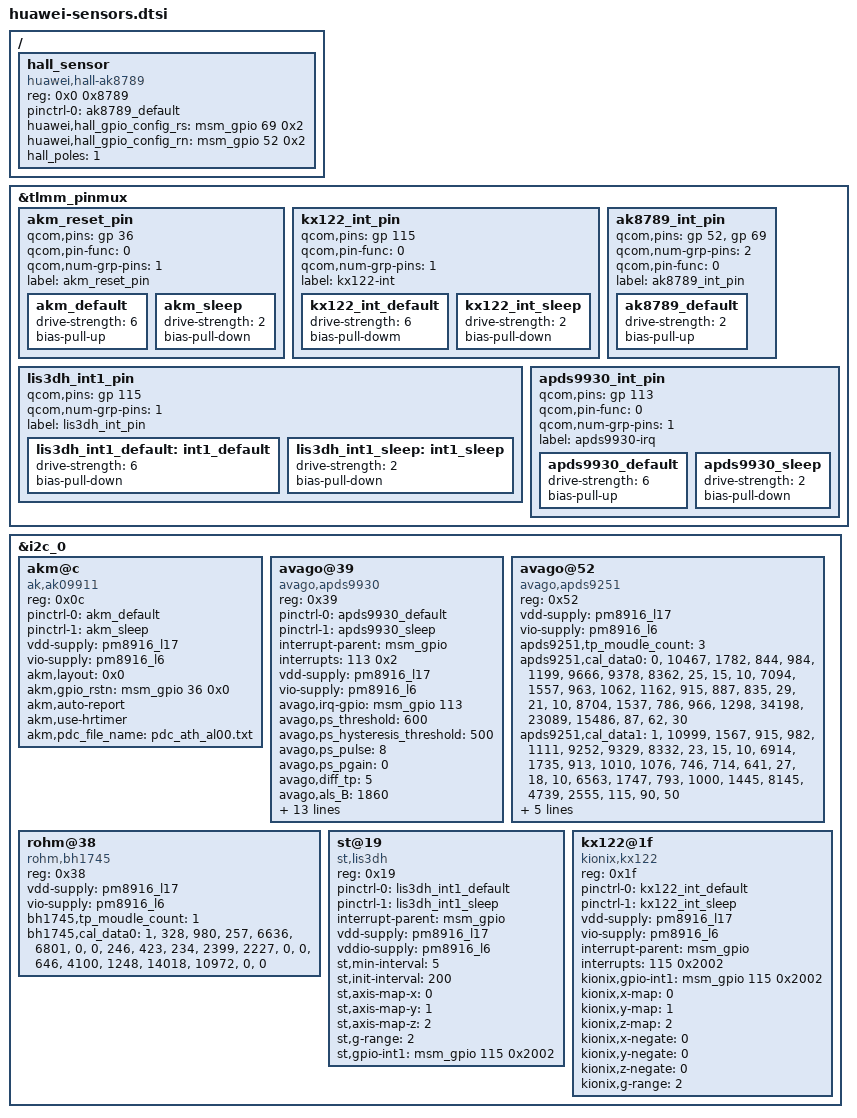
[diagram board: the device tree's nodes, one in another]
/* Copyright (c) 2013 The Linux Foundation. All rights reserved.
 *
 * This program is free software; you can redistribute it and/or modify
 * it under the terms of the GNU General Public License version 2 and
 * only version 2 as published by the Free Software Foundation.
 *
 * This program is distributed in the hope that it will be useful,
 * but WITHOUT ANY WARRANTY; without even the implied warranty of
 * MERCHANTABILITY or FITNESS FOR A PARTICULAR PURPOSE.  See the
 * GNU General Public License for more details.
 */

&tlmm_pinmux {
	akm_reset_pin {
		qcom,pins = <&gp 36>;
		qcom,pin-func = <0>;
		qcom,num-grp-pins = <1>;
		label = "akm_reset_pin";
		akm_default: akm_default {
			drive-strength = <6>;
			bias-pull-up;
		};
		akm_sleep: akm_sleep {
			drive-strength = <2>;
			bias-pull-down;
		};
	};

	kx122_int_pin {
		qcom,pins = <&gp 115>;
		qcom,pin-func = <0>;
		qcom,num-grp-pins = <1>;
		label = "kx122-int";
		kx122_int_default: kx122_int_default {
			drive-strength = <6>;
			bias-pull-dowm;
		};
        kx122_int_sleep: kx122_int_sleep {
			drive-strength = <2>;
			bias-pull-down;
		};
	};

	lis3dh_int1_pin {
		qcom,pins = <&gp 115>;
		qcom,num-grp-pins = <1>;
		label = "lis3dh_int_pin";
		lis3dh_int1_default: int1_default {
			drive-strength = <6>;
			bias-pull-down;
		};
		lis3dh_int1_sleep: int1_sleep {
			drive-strength = <2>;
			bias-pull-down;
		};
	};

	ak8789_int_pin {
		qcom,pins = <&gp 52>, <&gp 69>;
		qcom,num-grp-pins = <2>;
		qcom,pin-func = <0>;
		label = "ak8789_int_pin";
		ak8789_default: ak8789_default {
			  drive-strength = <2>;
			  bias-pull-up;
		};
	};

	apds9930_int_pin {
		qcom,pins = <&gp 113>;
		qcom,pin-func = <0>;
		qcom,num-grp-pins = <1>;
		label = "apds9930-irq";
		apds9930_default: apds9930_default {
			drive-strength = <6>;
			bias-pull-up;
		};
		apds9930_sleep: apds9930_sleep {
			drive-strength = <2>;
			bias-pull-down;
		};
	};
};

&i2c_0 { /* BLSP1 QUP2 */
	akm@c {
		compatible = "ak,ak09911";
		reg = <0x0c>;
		pinctrl-names = "default","sleep";
		pinctrl-0 = <&akm_default>;
		pinctrl-1 = <&akm_sleep>;
		vdd-supply = <&pm8916_l17>;
		vio-supply = <&pm8916_l6>;
		akm,layout = <0x0>;
		akm,gpio_rstn = <&msm_gpio 36 0x0>;
		akm,auto-report;
		akm,use-hrtimer;
		akm,pdc_file_name = "pdc_ath_al00.txt";
	//	akm,pdc_file_name = "pdc_FDR.txt";
		//akm,i2c-scl-gpio = <&msm_gpio 7 0x0>;
		//akm,i2c-sda-gpio = <&msm_gpio 6 0x0>;
	};

	avago@39 {
		compatible = "avago,apds9930";
		reg = <0x39>;
		pinctrl-names = "default","sleep";
		pinctrl-0 = <&apds9930_default>;
		pinctrl-1 = <&apds9930_sleep>;
		interrupt-parent = <&msm_gpio>;
		interrupts = <113 0x2>;
		vdd-supply = <&pm8916_l17>;
		vio-supply = <&pm8916_l6>;
		avago,irq-gpio = <&msm_gpio 113 0x2>;
		avago,ps_threshold = <600>;
		avago,ps_hysteresis_threshold = <500>;
		avago,ps_pulse = <8>;
		avago,ps_pgain = <0>;
		avago,diff_tp = <5>;
		avago,als_B = <1860>;
		avago,als_C = <750>;
		avago,als_D = <1290>;
		avago,ga_value = <48>;
		avago,ga_a_value = <112>;
		avago,ga_c_value = <450>;
		avago,ga_d_value = <162>;
		avago,window = <110>;
		avago,wave = <84>;
		avago,ga_e_value = <220>;
		avago,ga_f_value = <43>;
		avago,i2c-scl-gpio = <&msm_gpio 7 0x0>;
		avago,i2c-sda-gpio = <&msm_gpio 6 0x0>;
		avago,mix-light;
	};

	avago@52 {
		compatible = "avago,apds9251";
		reg = <0x52>;
		vdd-supply = <&pm8916_l17>;
		vio-supply = <&pm8916_l6>;
		apds9251,tp_moudle_count = <3>;
		/*[module_id] [CCT_M] [CCT_N] [H] [A] [D] [LUX_P] [LUX_Q] [LUX_R] [cofficient0] [cofficient1] [cofficient2]*/
		apds9251,cal_data0 = "0","10467","1782","844","984","1199","9666","9378","8362","25","15","10",
		/*[CCT_M] [CCT_N] [H] [A] [D] [LUX_P] [LUX_Q] [LUX_R] [cofficient0] [cofficient1] [cofficient2]*/
		"7094","1557","963","1062","1162","915","887","835","29","21","10",
		/*[CCT_M] [CCT_N] [H] [A] [D] [LUX_P] [LUX_Q] [LUX_R] [cofficient0] [cofficient1] [cofficient2]*/
		"8704","1537","786","966","1298","34198","23089","15486","87","62","30";
		/*[module_id] [CCT_M] [CCT_N] [H] [A] [D] [LUX_P] [LUX_Q] [LUX_R] [cofficient0] [cofficient1] [cofficient2]*/
		apds9251,cal_data1 = "1","10999","1567","915","982","1111","9252","9329","8332","23","15","10",
		/*[CCT_M] [CCT_N] [H] [A] [D] [LUX_P] [LUX_Q] [LUX_R] [cofficient0] [cofficient1] [cofficient2]*/
		"6914","1735","913","1010","1076","746","714","641","27","18","10",
		/*[CCT_M] [CCT_N] [H] [A] [D] [LUX_P] [LUX_Q] [LUX_R] [cofficient0] [cofficient1] [cofficient2]*/
		"6563","1747","793","1000","1445","8145","4739","2555","115","90","50";
		/*[module_id] [CCT_M] [CCT_N] [H] [A] [D] [LUX_P] [LUX_Q] [LUX_R] [cofficient0] [cofficient1] [cofficient2]*/
		apds9251,cal_data2 = "3","9976","1490","948","1048","1150","2470","2475","2261","25","15","10",
		/*[CCT_M] [CCT_N] [H] [A] [D] [LUX_P] [LUX_Q] [LUX_R] [cofficient0] [cofficient1] [cofficient2]*/
		"6491","1636","946","1054","1159","1043","1004","940","30","19","10",
		/*[CCT_M] [CCT_N] [H] [A] [D] [LUX_P] [LUX_Q] [LUX_R] [cofficient0] [cofficient1] [cofficient2]*/
		"14588","1008","939","1211","1256","13043","11270","9600","58","25","10";
	};

	rohm@38 {
		compatible = "rohm,bh1745";
		reg = <0x38>;
		vdd-supply = <&pm8916_l17>;
		vio-supply = <&pm8916_l6>;
		bh1745,tp_moudle_count = <1>;
		/*[module_id] [golden judge] r[0] r[1] g[0] g[1] b[0] b[1]*/
		bh1745,cal_data0 = "1","328","980","257","6636","6801","0","0",
		/*[white judge] r[0] r[1] g[0]  g[1] b[0] b[1]*/
		"246","423","234","2399","2227","0","0",
		/*[blue judge] r[0] r[1] g[0] g[1] b[0] b[1]*/
		"646","4100","1248","14018","10972","0","0";
	};

	st@19 {
		compatible = "st,lis3dh";
		reg = <0x19>;
		pinctrl-names = "lis3dh_default","lis3dh_sleep";
		pinctrl-0 = <&lis3dh_int1_default>;
		pinctrl-1 = <&lis3dh_int1_sleep>;
		interrupt-parent = <&msm_gpio>;
		//interrupts = <115 0x2002>;
		vdd-supply = <&pm8916_l17>;
		vddio-supply = <&pm8916_l6>;
		st,min-interval = <5>;
		st,init-interval = <200>;
		st,axis-map-x = <0>;
		st,axis-map-y = <1>;
		st,axis-map-z = <2>;
		st,g-range = <2>;
		st,gpio-int1 = <&msm_gpio 115 0x2002>;
		// st,negate-x;
		// st,negate-y;
	};

	kx122@1f { /* Kionix accelerometer */
		compatible = "kionix,kx122";
		reg = <0x1f>;
		pinctrl-names = "kx122_int_default", "kx122_int_sleep";
		pinctrl-0 = <&kx122_int_default>;
		pinctrl-1 = <&kx122_int_sleep>;
		vdd-supply = <&pm8916_l17>;
		vio-supply = <&pm8916_l6>;
		interrupt-parent = <&msm_gpio>;
		interrupts = <115 0x2002>;
		kionix,gpio-int1 = <&msm_gpio 115 0x2002>;
		kionix,x-map = <0>;
		kionix,y-map = <1>;
		kionix,z-map = <2>;
		kionix,x-negate = <0>;
		kionix,y-negate = <0>;
		kionix,z-negate = <0>;
		kionix,g-range = <2>;
		//kionix,use-drdy-int;
	};
};

/ {
	hall_sensor {
		compatible = "huawei,hall-ak8789";
		reg = <0x0 0x8789>;
		pinctrl-names = "default";
		pinctrl-0 = <&ak8789_default>;
		huawei,hall_gpio_config_rs = <&msm_gpio 69 0x2>;
		huawei,hall_gpio_config_rn = <&msm_gpio 52 0x2>;
		hall_poles = <1>;
		status = "ok";
	};
};
